# slm32x030 register map
Vendor: Keil; File version: 1.0.1
CPU: CM0 r2p1, little endian, no MPU, no FPU, 4 interrupt priority bits
Registers are 32-bit, read-write, reset 0x0 unless marked. A register's access mark holds for its fields unless they carry their own. Offsets are from the block's base; [hi:lo] are bit positions; {n}, {i} and the like mark numbered series.

## CRC
Base 0x40023000
0x00 DR reset 0xFFFFFFFF — CRC_DR
  [31:0] DR — Later Add Description
0x04 IDR — CRC_IDR
  [31:0] IDR — Later Add Description
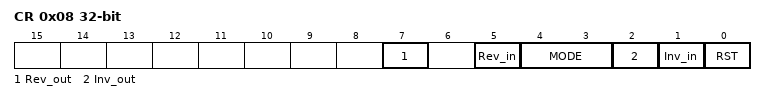
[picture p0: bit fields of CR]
0x08 CR access not given — CRC_CR
  [7] Rev_out — Later Add Description
  [5] Rev_in — Later Add Description
  [4:3] MODE — Later Add Description
  [2] Inv_out — Later Add Description
  [1] Inv_in — Later Add Description
  [0] RST — Later Add Description
0x0C INIT access not given reset 0xFFFFFFFF — CRC_INIT
  [31:0] CRC_INIT — Later Add Description

## PMU
Base 0x40007000
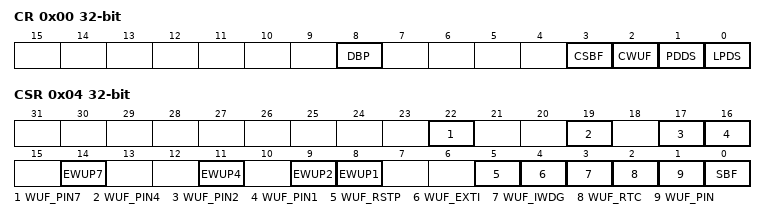
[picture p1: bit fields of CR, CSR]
0x00 CR access not given — PMU_CR
  [8] DBP rw — Later Add Description
  [3] CSBF — Later Add Description
  [2] CWUF — Later Add Description
  [1] PDDS rw — Later Add Description
  [0] LPDS rw — Later Add Description
0x04 CSR access per field — PMU_CSR
  [22] WUF_PIN7 rw — Later Add Description
  [19] WUF_PIN4 rw — Later Add Description
  [17] WUF_PIN2 rw — Later Add Description
  [16] WUF_PIN1 rw — Later Add Description
  [14] EWUP7 rw — Later Add Description
  [11] EWUP4 rw — Later Add Description
  [9] EWUP2 rw — Later Add Description
  [8] EWUP1 rw — Later Add Description
  [5] WUF_RSTP ro — Later Add Description
  [4] WUF_EXTI ro — Later Add Description
  [3] WUF_IWDG ro — Later Add Description
  [2] WUF_RTC ro — Later Add Description
  [1] WUF_PIN ro — Later Add Description
  [0] SBF ro — Later Add Description

## GPIOA — Io function
Base 0x48000000
Same registers: GPIOB 0x48000400, GPIOC 0x48000800, GPIOD 0x48000C00
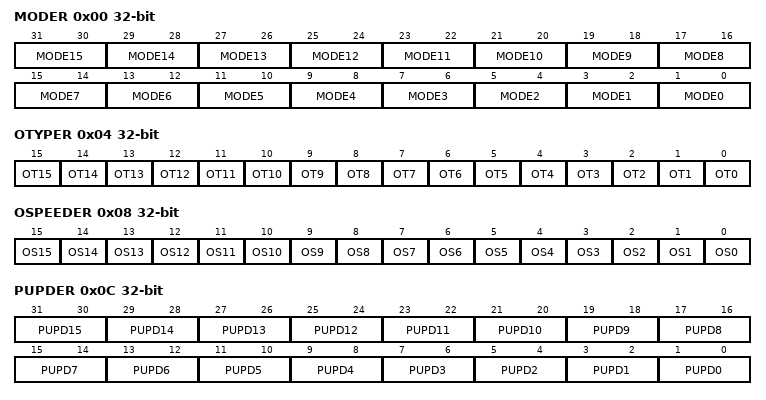
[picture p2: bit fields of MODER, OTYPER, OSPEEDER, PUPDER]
0x00 MODER — GPRx_MODER
  [2n+1:2n] MODE{n} (n=0..15) — Later Add Description
0x04 OTYPER — GPRx_OTYPER
  [n] OT{n} (n=0..15) — Later Add Description
0x08 OSPEEDER — GPRx_OSPEEDER
  [n] OS{n} (n=0..15) — Later Add Description
0x0C PUPDER — GPRx_PUPDER
  [2n+1:2n] PUPD{n} (n=0..15) — Later Add Description
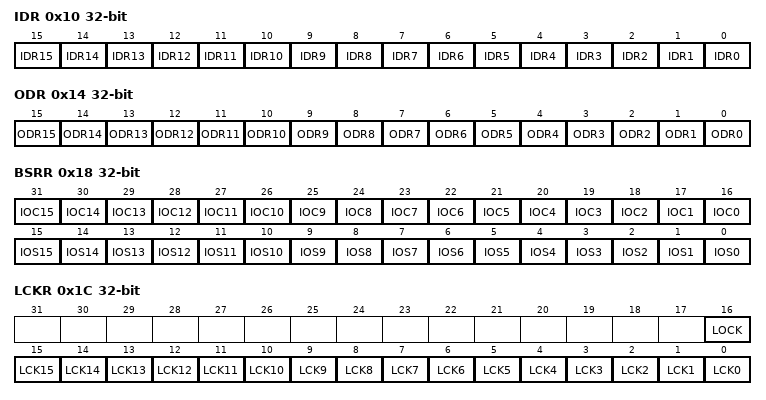
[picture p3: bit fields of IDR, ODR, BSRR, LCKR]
0x10 IDR — GPRx_IDR
  [n] IDR{n} (n=0..15) — Later Add Description
0x14 ODR — GPRx_ODR
  [n] ODR{n} (n=0..15) — Later Add Description
0x18 BSRR — GPRx_BSRR
  [n+16] IOC{n} (n=0..15) — Later Add Description
  [n] IOS{n} (n=0..15) — Later Add Description
0x1C LCKR — GPRx_LCKR
  [16] LOCK — Later Add Description
  [n] LCK{n} (n=0..15) — Later Add Description
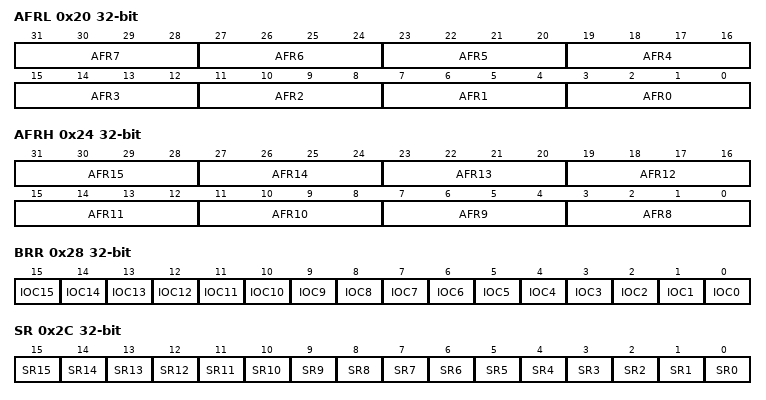
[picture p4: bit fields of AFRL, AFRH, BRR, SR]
0x20 AFRL — GPRx_AFRL
  [4n+3:4n] AFR{n} (n=0..7) — Later Add Description
0x24 AFRH — GPRx_AFRH
  [4n-29:4n-32] AFR{n} (n=8..15) — Later Add Description
0x28 BRR — GPRx_BRR
  [n] IOC{n} (n=0..15) — Later Add Description
0x2C SR — GPRx_SR
  [n] SR{n} (n=0..15) — Later Add Description

## SYSCFG — system configuration(SYSCFG)
Base 0x40010000
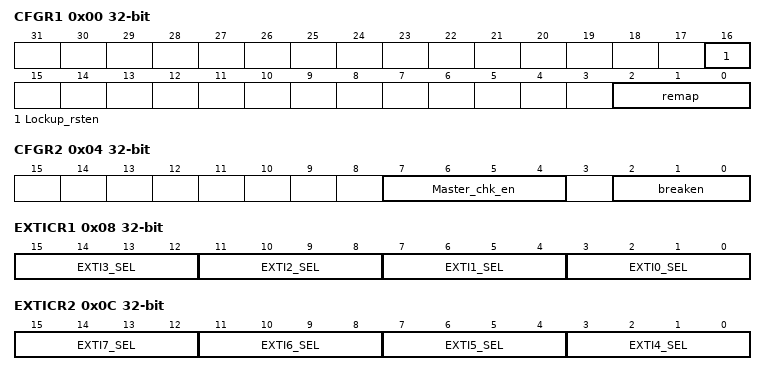
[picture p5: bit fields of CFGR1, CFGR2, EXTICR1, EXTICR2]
0x00 CFGR1 access per field — SYSCFG_CFGR1
  [16] Lockup_rsten rw — Later Add Description
  [2:0] remap ro — Later Add Description
0x04 CFGR2 — SYSCFG_CFGR2
  [7:4] Master_chk_en — Later Add Description
  [2:0] breaken — Later Add Description
0x08 EXTICR1 — SYSCFG_EXTICR1
  [4n+3:4n] EXTI{n}_SEL (n=0..3) — Later Add Description
0x0C EXTICR2 — SYSCFG_EXTICR2
  [4n-13:4n-16] EXTI{n}_SEL (n=4..7) — Later Add Description
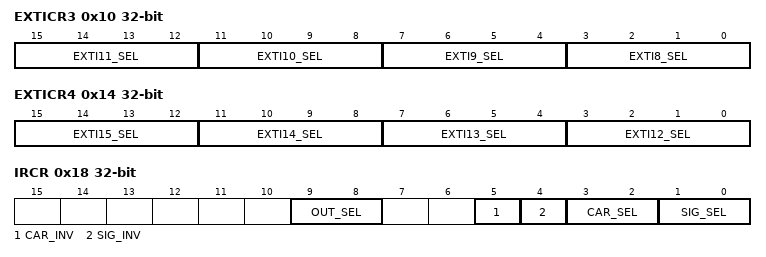
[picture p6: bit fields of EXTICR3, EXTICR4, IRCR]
0x10 EXTICR3 — SYSCFG_EXTICR3
  [4n-29:4n-32] EXTI{n}_SEL (n=8..11) — Later Add Description
0x14 EXTICR4 — SYSCFG_EXTICR4
  [4n-45:4n-48] EXTI{n}_SEL (n=12..15) — Later Add Description
0x18 IRCR — SYSCFG_IRCR
  [9:8] OUT_SEL — Later Add Description
  [5] CAR_INV — Later Add Description
  [4] SIG_INV — Later Add Description
  [3:2] CAR_SEL — Later Add Description
  [1:0] SIG_SEL — Later Add Description

## EXTI — Interruptions and Events(IEMU)
Base 0x40010400
0x00 IMR — EXTI_IMR
  [23:0] MRx — Later Add Description
0x04 EMR — EXTI_EMR
  [23:0] EMRx — Later Add Description
0x08 RTSR — EXTI_RTSR
  [23:0] TRx — Later Add Description
0x0C FTSR — EXTI_FTSR
  [23:0] TRx — Later Add Description
0x10 SWIER — EXTI_SWIER
  [23:0] SWIERx — Later Add Description
0x14 PR access not given — EXTI_PR
  [23:0] PRx — Later Add Description
